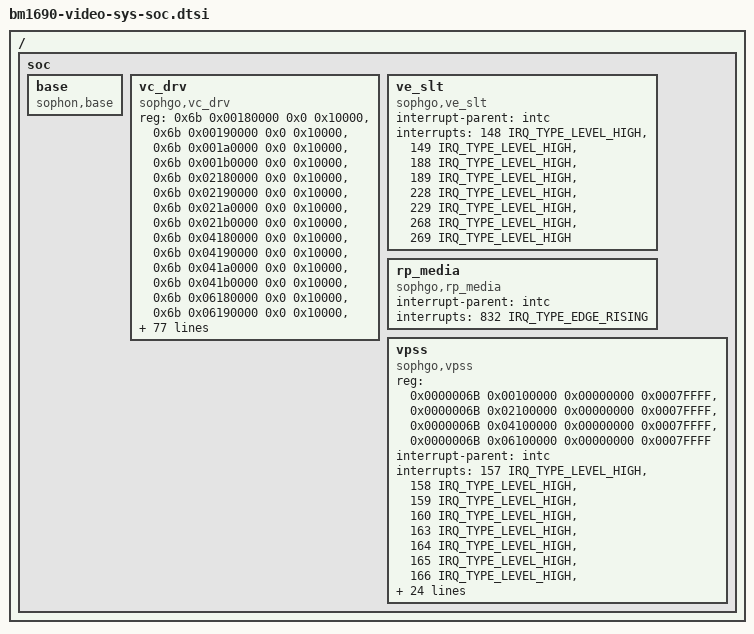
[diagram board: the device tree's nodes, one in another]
// SPDX-License-Identifier: (GPL-2.0 OR MIT)
/*
 * Copyright (C) 2022 Sophgo Technology Inc. All rights reserved.
 */

/ {
	soc {
		base {
			compatible = "sophon,base";
		};

		// video & jpeg
		vc_drv {
			compatible = "sophgo,vc_drv";
			reg = <0x6b 0x00180000 0x0 0x10000>, <0x6b 0x00190000 0x0 0x10000>,
				<0x6b 0x001a0000 0x0 0x10000>, <0x6b 0x001b0000 0x0 0x10000>,
				<0x6b 0x02180000 0x0 0x10000>, <0x6b 0x02190000 0x0 0x10000>,
				<0x6b 0x021a0000 0x0 0x10000>, <0x6b 0x021b0000 0x0 0x10000>,
				<0x6b 0x04180000 0x0 0x10000>, <0x6b 0x04190000 0x0 0x10000>,
				<0x6b 0x041a0000 0x0 0x10000>, <0x6b 0x041b0000 0x0 0x10000>,
				<0x6b 0x06180000 0x0 0x10000>, <0x6b 0x06190000 0x0 0x10000>,
				<0x6b 0x061a0000 0x0 0x10000>, <0x6b 0x061b0000 0x0 0x10000>,
				<0x00 0x00010000 0x0 0x10000>, <0x00 0x00020000 0x0 0x10000>,
				<0x00 0x02010000 0x0 0x10000>, <0x00 0x02020000 0x0 0x10000>,
				<0x00 0x04010000 0x0 0x10000>, <0x00 0x04020000 0x0 0x10000>,
				<0x00 0x06010000 0x0 0x10000>, <0x00 0x06020000 0x0 0x10000>,
				<0x6b 0x00040000 0x0 0x10000>, <0x6b 0x00042000 0x0 0x10000>,
				<0x6b 0x02040000 0x0 0x10000>, <0x6b 0x02042000 0x0 0x10000>,
				<0x6b 0x04040000 0x0 0x10000>, <0x6b 0x04042000 0x0 0x10000>,
				<0x6b 0x06040000 0x0 0x10000>, <0x6b 0x06042000 0x0 0x10000>,
				<0x10 0x80000000 0x3 0x00000000>,<0x13 0x80000000 0x1 0x00000000>;

			interrupt-parent = <&intc>;
			interrupts =<161 IRQ_TYPE_LEVEL_HIGH>, <162 IRQ_TYPE_LEVEL_HIGH>,
				<167 IRQ_TYPE_LEVEL_HIGH>, <168 IRQ_TYPE_LEVEL_HIGH>,
				<201 IRQ_TYPE_LEVEL_HIGH>, <202 IRQ_TYPE_LEVEL_HIGH>,
				<207 IRQ_TYPE_LEVEL_HIGH>, <208 IRQ_TYPE_LEVEL_HIGH>,
				<241 IRQ_TYPE_LEVEL_HIGH>, <242 IRQ_TYPE_LEVEL_HIGH>,
				<247 IRQ_TYPE_LEVEL_HIGH>, <248 IRQ_TYPE_LEVEL_HIGH>,
				<281 IRQ_TYPE_LEVEL_HIGH>, <282 IRQ_TYPE_LEVEL_HIGH>,
				<287 IRQ_TYPE_LEVEL_HIGH>, <288 IRQ_TYPE_LEVEL_HIGH>,
				<136 IRQ_TYPE_LEVEL_HIGH>, <140 IRQ_TYPE_LEVEL_HIGH>,
				<176 IRQ_TYPE_LEVEL_HIGH>, <180 IRQ_TYPE_LEVEL_HIGH>,
				<216 IRQ_TYPE_LEVEL_HIGH>, <220 IRQ_TYPE_LEVEL_HIGH>,
				<256 IRQ_TYPE_LEVEL_HIGH>, <260 IRQ_TYPE_LEVEL_HIGH>,
				<137 IRQ_TYPE_LEVEL_HIGH>, <141 IRQ_TYPE_LEVEL_HIGH>,
				<177 IRQ_TYPE_LEVEL_HIGH>, <181 IRQ_TYPE_LEVEL_HIGH>,
				<217 IRQ_TYPE_LEVEL_HIGH>, <221 IRQ_TYPE_LEVEL_HIGH>,
				<257 IRQ_TYPE_LEVEL_HIGH>, <261 IRQ_TYPE_LEVEL_HIGH>,
				<138 IRQ_TYPE_LEVEL_HIGH>, <142 IRQ_TYPE_LEVEL_HIGH>,
				<178 IRQ_TYPE_LEVEL_HIGH>, <182 IRQ_TYPE_LEVEL_HIGH>,
				<218 IRQ_TYPE_LEVEL_HIGH>, <222 IRQ_TYPE_LEVEL_HIGH>,
				<258 IRQ_TYPE_LEVEL_HIGH>, <262 IRQ_TYPE_LEVEL_HIGH>,
				<139 IRQ_TYPE_LEVEL_HIGH>, <143 IRQ_TYPE_LEVEL_HIGH>,
				<179 IRQ_TYPE_LEVEL_HIGH>, <183 IRQ_TYPE_LEVEL_HIGH>,
				<219 IRQ_TYPE_LEVEL_HIGH>, <223 IRQ_TYPE_LEVEL_HIGH>,
				<259 IRQ_TYPE_LEVEL_HIGH>, <263 IRQ_TYPE_LEVEL_HIGH>,
				<148 IRQ_TYPE_LEVEL_HIGH>, <149 IRQ_TYPE_LEVEL_HIGH>,
				<188 IRQ_TYPE_LEVEL_HIGH>, <189 IRQ_TYPE_LEVEL_HIGH>,
				<228 IRQ_TYPE_LEVEL_HIGH>, <229 IRQ_TYPE_LEVEL_HIGH>,
				<268 IRQ_TYPE_LEVEL_HIGH>, <269 IRQ_TYPE_LEVEL_HIGH>;
		};

		ve_slt {
			compatible = "sophgo,ve_slt";
			interrupt-parent = <&intc>;
			interrupts =<148 IRQ_TYPE_LEVEL_HIGH>, <149 IRQ_TYPE_LEVEL_HIGH>,
				<188 IRQ_TYPE_LEVEL_HIGH>, <189 IRQ_TYPE_LEVEL_HIGH>,
				<228 IRQ_TYPE_LEVEL_HIGH>, <229 IRQ_TYPE_LEVEL_HIGH>,
				<268 IRQ_TYPE_LEVEL_HIGH>, <269 IRQ_TYPE_LEVEL_HIGH>;
		};

		rp_media{
			compatible = "sophgo,rp_media";
			interrupt-parent = <&intc>;
			interrupts =<832 IRQ_TYPE_EDGE_RISING>;
		};

		vpss {
			compatible = "sophgo,vpss";
			reg = <0x0000006B 0x00100000 0x00000000 0x0007FFFF>,
				<0x0000006B 0x02100000 0x00000000 0x0007FFFF>,
				<0x0000006B 0x04100000 0x00000000 0x0007FFFF>,
				<0x0000006B 0x06100000 0x00000000 0x0007FFFF>;

			interrupt-parent = <&intc>;
			interrupts = <157 IRQ_TYPE_LEVEL_HIGH>, <158 IRQ_TYPE_LEVEL_HIGH>,
				<159 IRQ_TYPE_LEVEL_HIGH>, <160 IRQ_TYPE_LEVEL_HIGH>,
				<163 IRQ_TYPE_LEVEL_HIGH>, <164 IRQ_TYPE_LEVEL_HIGH>,
				<165 IRQ_TYPE_LEVEL_HIGH>, <166 IRQ_TYPE_LEVEL_HIGH>,
				<197 IRQ_TYPE_LEVEL_HIGH>, <198 IRQ_TYPE_LEVEL_HIGH>,
				<199 IRQ_TYPE_LEVEL_HIGH>, <200 IRQ_TYPE_LEVEL_HIGH>,
				<203 IRQ_TYPE_LEVEL_HIGH>, <204 IRQ_TYPE_LEVEL_HIGH>,
				<205 IRQ_TYPE_LEVEL_HIGH>, <206 IRQ_TYPE_LEVEL_HIGH>,
				<237 IRQ_TYPE_LEVEL_HIGH>, <238 IRQ_TYPE_LEVEL_HIGH>,
				<239 IRQ_TYPE_LEVEL_HIGH>, <240 IRQ_TYPE_LEVEL_HIGH>,
				<243 IRQ_TYPE_LEVEL_HIGH>, <244 IRQ_TYPE_LEVEL_HIGH>,
				<245 IRQ_TYPE_LEVEL_HIGH>, <246 IRQ_TYPE_LEVEL_HIGH>,
				<277 IRQ_TYPE_LEVEL_HIGH>, <278 IRQ_TYPE_LEVEL_HIGH>,
				<279 IRQ_TYPE_LEVEL_HIGH>, <280 IRQ_TYPE_LEVEL_HIGH>,
				<283 IRQ_TYPE_LEVEL_HIGH>, <284 IRQ_TYPE_LEVEL_HIGH>,
				<285 IRQ_TYPE_LEVEL_HIGH>, <286 IRQ_TYPE_LEVEL_HIGH>;
		};
	};
};
